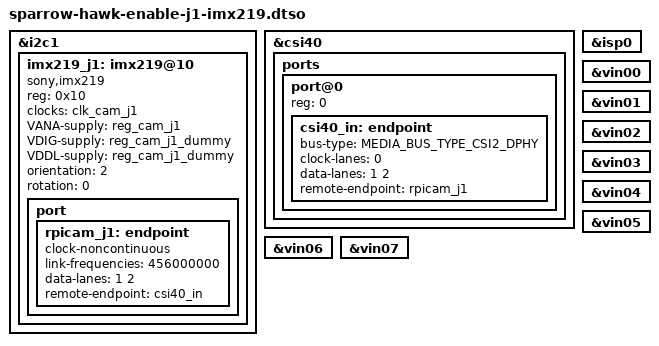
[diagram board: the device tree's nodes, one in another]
/dts-v1/;
/plugin/;

#include <dt-bindings/media/video-interfaces.h>

/* Page 29 / CSI_IF_CN / CAM_CN0 */
&i2c1 {
	status = "okay";

	imx219_j1: imx219@10 {
		compatible = "sony,imx219";
		reg = <0x10>;
		status = "okay";

		clocks = <&clk_cam_j1>;
		clock-names = "xclk";

		VANA-supply = <&reg_cam_j1>;
		VDIG-supply = <&reg_cam_j1_dummy>;
		VDDL-supply = <&reg_cam_j1_dummy>;

		orientation = <2>;
		rotation = <0>;

		port {
			rpicam_j1: endpoint {
				clock-noncontinuous;
				link-frequencies = /bits/ 64 <456000000>;
				data-lanes = <1 2>;
				remote-endpoint = <&csi40_in>;
			};
		};
	};
};

/* Page 29 / CSI_IF_CN */
&csi40 {
	status = "okay";

	ports {
		#address-cells = <1>;
		#size-cells = <0>;

		port@0 {
			reg = <0>;

			csi40_in: endpoint {
				bus-type = <MEDIA_BUS_TYPE_CSI2_DPHY>;
				clock-lanes = <0>;
				data-lanes = <1 2>;
				remote-endpoint = <&rpicam_j1>;
			};
		};
	};
};

&isp0 {
	status = "okay";
};

&vin00 {
	status = "okay";
};

&vin01 {
        status = "okay";
};

&vin02 {
        status = "okay";
};

&vin03 {
        status = "okay";
};

&vin04 {
        status = "okay";
};

&vin05 {
        status = "okay";
};

&vin06 {
        status = "okay";
};

&vin07 {
	status = "okay";
};

